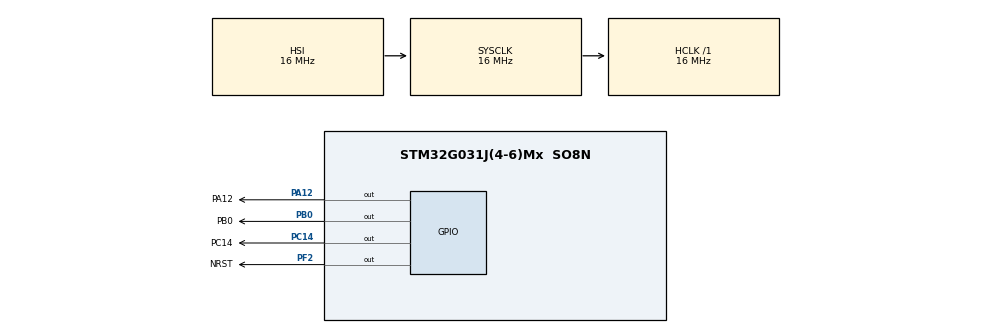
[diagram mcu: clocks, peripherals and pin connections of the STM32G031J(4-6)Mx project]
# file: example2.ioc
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Mcu.Family=STM32G0
Mcu.Name=STM32G031J(4-6)Mx
Mcu.Package=SO8N
NVIC.TIM1_BRK_UP_TRG_COM_IRQn=true\:0\:0\:false\:false\:true\:true\:true
PA12\ [PA10].GPIO_Label=PA12
PA12\ [PA10].GPIO_Speed=GPIO_SPEED_FREQ_MEDIUM
PA12\ [PA10].Signal=GPIO_Output
PA13.GPIO_Label=SWDIO
PA13.Mode=Serial_Wire
PA13.Signal=SYS_SWDIO
PA14-BOOT0.GPIO_Label=SWCLK
PA14-BOOT0.Mode=Serial_Wire
PA14-BOOT0.Signal=SYS_SWCLK
PB0.GPIO_Label=PB0
PB0.Signal=GPIO_Output
PC14-OSC32_IN\ (PC14).GPIO_Label=PC14
PC14-OSC32_IN\ (PC14).Signal=GPIO_Output
PF2\ -\ NRST.GPIO_Label=NRST
PF2\ -\ NRST.Signal=GPIO_Output
ProjectManager.HeapSize=0x200
ProjectManager.StackSize=0x400
ProjectManager.TargetToolchain=SW4STM32
RCC.AHBFreq_Value=16000000
RCC.CortexFreq_Value=16000000
RCC.EXTERNAL_CLOCK_VALUE=12288000
RCC.HCLKFreq_Value=16000000
RCC.HSE_VALUE=8000000
RCC.HSI_VALUE=16000000
RCC.LSE_VALUE=32768
RCC.SYSCLKFreq_VALUE=16000000
RCC.VCOOutputFreq_Value=128000000
TIM1.Channel-Output\ Compare5\ No\ Output=TIM_CHANNEL_5
TIM1.ClockDivision=TIM_CLOCKDIVISION_DIV4
TIM1.OCPolarity_5=TIM_OCPOLARITY_HIGH
TIM1.Pulse-Output\ Compare5\ No\ Output=60000
TIM1.RepetitionCounter=61
VP_TIM1_VS_no_output5.Mode=Output Compare5 No Output
board=custom

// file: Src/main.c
/* USER CODE BEGIN Header */
/**
  ******************************************************************************
  * @file           : main.c
  * @brief          : Main program body
  ******************************************************************************
  * @attention
  *
  * <h2><center>&copy; Copyright (c) 2020 STMicroelectronics.
  * All rights reserved.</center></h2>
  *
  * This software component is licensed by ST under BSD 3-Clause license,
  * the "License"; You may not use this file except in compliance with the
  * License. You may obtain a copy of the License at:
  *                        opensource.org/licenses/BSD-3-Clause
  *
  ******************************************************************************
  */
/* USER CODE END Header */

#include "main.h"
#include "tim.h"
#include "gpio.h"

void SystemClock_Config(void);

int main(void)
{

  /* MCU Configuration--------------------------------------------------------*/

  /* Reset of all peripherals, Initializes the Flash interface and the Systick. */
  HAL_Init();

  /* Configure the system clock */
  SystemClock_Config();

  /* Initialize all configured peripherals */
  MX_GPIO_Init();
  MX_TIM1_Init();
  /* USER CODE BEGIN 2 */

  HAL_GPIO_WritePin(PC14_GPIO_Port, PC14_Pin, GPIO_PIN_SET);

  /*Configure GPIO pin Output Level */
  //HAL_GPIO_WritePin(GPIOF, GPIO_PIN_2, GPIO_PIN_SET);

  /*Configure GPIO pin Output Level */
  HAL_GPIO_WritePin(PB0_GPIO_Port, PB0_Pin, GPIO_PIN_SET);

  /*Configure GPIO pin Output Level */
  HAL_GPIO_WritePin(PA12_GPIO_Port, PA12_Pin, GPIO_PIN_SET);
  /* USER CODE END 2 */
  uint32_t count = 0;
#define CMDC0DE_MAX 100000

  /* Infinite loop */
  /* USER CODE BEGIN WHILE */
  while (1)
  {
	  if((++count%CMDC0DE_MAX)==CMDC0DE_MAX/10) {
		  HAL_GPIO_TogglePin(PC14_GPIO_Port,PC14_Pin);
	  }
	  if((count%CMDC0DE_MAX)==CMDC0DE_MAX/50) {
		  HAL_GPIO_TogglePin(PB0_GPIO_Port,PB0_Pin);
	  }
	  if((count%CMDC0DE_MAX)==CMDC0DE_MAX/75) {
		  HAL_GPIO_TogglePin(PA12_GPIO_Port,PA12_Pin);
	  }
	  if(count>CMDC0DE_MAX) {
		  count = 0;
	  }
    /* USER CODE END WHILE */

  }
}

void SystemClock_Config(void)
{
  RCC_OscInitTypeDef RCC_OscInitStruct = {0};
  RCC_ClkInitTypeDef RCC_ClkInitStruct = {0};
  RCC_PeriphCLKInitTypeDef PeriphClkInit = {0};

  /** Configure the main internal regulator output voltage
  */
  HAL_PWREx_ControlVoltageScaling(PWR_REGULATOR_VOLTAGE_SCALE1);
  /** Initializes the CPU, AHB and APB busses clocks
  */
  RCC_OscInitStruct.OscillatorType = RCC_OSCILLATORTYPE_HSI;
  RCC_OscInitStruct.HSIState = RCC_HSI_ON;
  RCC_OscInitStruct.HSIDiv = RCC_HSI_DIV1;
  RCC_OscInitStruct.HSICalibrationValue = RCC_HSICALIBRATION_DEFAULT;
  RCC_OscInitStruct.PLL.PLLState = RCC_PLL_NONE;
  if (HAL_RCC_OscConfig(&RCC_OscInitStruct) != HAL_OK)
  {
    Error_Handler();
  }
  /** Initializes the CPU, AHB and APB busses clocks
  */
  RCC_ClkInitStruct.ClockType = RCC_CLOCKTYPE_HCLK|RCC_CLOCKTYPE_SYSCLK
                              |RCC_CLOCKTYPE_PCLK1;
  RCC_ClkInitStruct.SYSCLKSource = RCC_SYSCLKSOURCE_HSI;
  RCC_ClkInitStruct.AHBCLKDivider = RCC_SYSCLK_DIV1;
  RCC_ClkInitStruct.APB1CLKDivider = RCC_HCLK_DIV1;

  if (HAL_RCC_ClockConfig(&RCC_ClkInitStruct, FLASH_LATENCY_0) != HAL_OK)
  {
    Error_Handler();
  }
  /** Initializes the peripherals clocks
  */
  PeriphClkInit.PeriphClockSelection = RCC_PERIPHCLK_TIM1;
  PeriphClkInit.Tim1ClockSelection = RCC_TIM1CLKSOURCE_PCLK1;
  if (HAL_RCCEx_PeriphCLKConfig(&PeriphClkInit) != HAL_OK)
  {
    Error_Handler();
  }
}

void Error_Handler(void)
{
}

/************************ (C) COPYRIGHT STMicroelectronics *****END OF FILE****/
